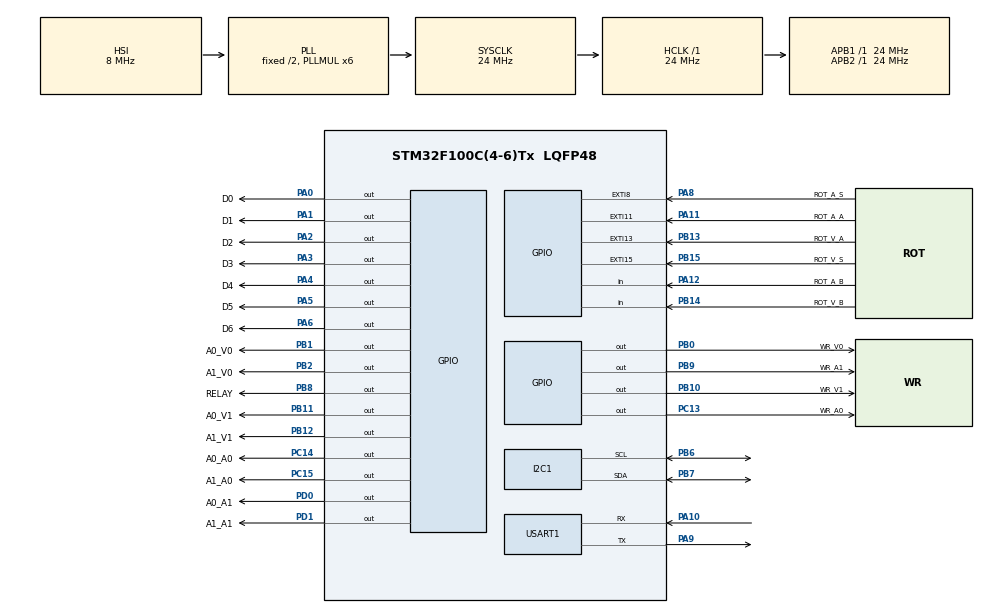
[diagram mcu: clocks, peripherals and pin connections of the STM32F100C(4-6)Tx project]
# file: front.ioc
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Mcu.Family=STM32F1
PB14.GPIO_Label=ROT_V_B
PA6.GPIO_Label=D6
PB0.GPIO_Label=WR_V0
PB13.GPIO_Label=ROT_V_A
PB11.Signal=GPIO_Output
PB13.Signal=GPXTI13
PB15.Signal=GPXTI15
PC15-OSC32_OUT.GPIO_Label=A1_A0
RCC.SYSCLKSource=RCC_SYSCLKSOURCE_PLLCLK
ProjectManager.StackSize=0x400
PD1-OSC_OUT.Signal=GPIO_Output
PD1-OSC_OUT.GPIO_Label=A1_A1
PA12.Signal=GPIO_Input
TIM15.Prescaler=24
RCC.HCLKFreq_Value=24000000
RCC.APB2TimFreq_Value=24000000
PB6.Signal=I2C1_SCL
PB6.Mode=I2C
RCC.AHBFreq_Value=24000000
NVIC.EXTI15_10_IRQn=true\:0\:0\:false\:false\:true\:true\:true
PB2.Signal=GPIO_Output
RCC.PLLMUL=RCC_PLL_MUL6
TIM15.Period=1000
PB12.GPIO_Label=A1_V1
PA14.Mode=Serial_Wire
PB1.GPIO_Label=A0_V0
PB7.Signal=I2C1_SDA
PA8.Signal=GPXTI8
Mcu.Package=LQFP48
PB9.Signal=GPIO_Output
PB1.Signal=GPIO_Output
PA6.Signal=GPIO_Output
PA2.GPIO_Label=D2
PA10.Signal=USART1_RX
RCC.APB1TimFreq_Value=24000000
PC14-OSC32_IN.GPIO_Label=A0_A0
NVIC.USART1_IRQn=true\:0\:0\:false\:false\:true\:true\:true
PA4.GPIO_Label=D4
PA3.Signal=GPIO_Output
PB9.GPIO_Label=WR_A1
PA10.Mode=Asynchronous
PB11.GPIO_Label=A0_V1
PC13-TAMPER-RTC.Signal=GPIO_Output
PA11.GPIO_Label=ROT_A_A
PD0-OSC_IN.Signal=GPIO_Output
PC14-OSC32_IN.Signal=GPIO_Output
PB13.GPIO_ModeDefaultEXTI=GPIO_MODE_IT_RISING_FALLING
PA12.GPIO_Label=ROT_A_B
PA0-WKUP.GPIO_Label=D0
PA0-WKUP.Signal=GPIO_Output
PA13.Signal=SYS_JTMS-SWDIO
PB8.GPIO_Label=RELAY
PA9.Mode=Asynchronous
PA8.GPIO_Label=ROT_A_S
ProjectManager.TargetToolchain=STM32CubeIDE
PB10.GPIO_Label=WR_V1
PA9.Signal=USART1_TX
PC15-OSC32_OUT.Signal=GPIO_Output
PA1.Signal=GPIO_Output
PB10.Signal=GPIO_Output
PB14.Signal=GPIO_Input
PA5.Signal=GPIO_Output
NVIC.TIM1_BRK_TIM15_IRQn=true\:0\:0\:false\:false\:true\:true\:true
board=custom
PD0-OSC_IN.GPIO_Label=A0_A1
PC13-TAMPER-RTC.GPIO_Label=WR_A0
RCC.APB2Freq_Value=24000000
PB15.GPIO_Label=ROT_V_S
PA1.GPIO_Label=D1
PA13.Mode=Serial_Wire
Mcu.Name=STM32F100C(4-6)Tx
PA2.Signal=GPIO_Output
PA4.Signal=GPIO_Output
RCC.SYSCLKFreq_VALUE=24000000
PA5.GPIO_Label=D5
USART1.VirtualMode=VM_ASYNC
PB7.Mode=I2C
PA11.Signal=GPXTI11
VP_TIM15_VS_ClockSourceINT.Mode=Internal
NVIC.EXTI9_5_IRQn=true\:0\:0\:false\:false\:true\:true\:true
PA14.Signal=SYS_JTCK-SWCLK
PB2.GPIO_Label=A1_V0
ProjectManager.HeapSize=0x200
NVIC.PriorityGroup=NVIC_PRIORITYGROUP_4
PB8.Signal=GPIO_Output
PA11.GPIO_ModeDefaultEXTI=GPIO_MODE_IT_RISING_FALLING
RCC.APB1Freq_Value=24000000
PB0.Signal=GPIO_Output
PB12.Signal=GPIO_Output
PA3.GPIO_Label=D3

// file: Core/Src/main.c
/* USER CODE BEGIN Header */
/**
  ******************************************************************************
  * @file           : main.c
  * @brief          : Main program body
  ******************************************************************************
  * @attention
  *
  * <h2><center>&copy; Copyright (c) 2021 STMicroelectronics.
  * All rights reserved.</center></h2>
  *
  * This software component is licensed by ST under BSD 3-Clause license,
  * the "License"; You may not use this file except in compliance with the
  * License. You may obtain a copy of the License at:
  *                        opensource.org/licenses/BSD-3-Clause
  *
  ******************************************************************************
  */
/* USER CODE END Header */
#include "main.h"
#include "i2c.h"
#include "tim.h"
#include "usart.h"
#include "gpio.h"

/* USER CODE BEGIN Includes */
#include "../../Application/Application/start.h"
/* USER CODE END Includes */

/* USER CODE BEGIN PV */
uint8_t globalUartReceiveBuffer[1];
/* USER CODE END PV */

void SystemClock_Config(void);

int main(void)
{

  /* MCU Configuration--------------------------------------------------------*/

  /* Reset of all peripherals, Initializes the Flash interface and the Systick. */
  HAL_Init();

  /* Configure the system clock */
  SystemClock_Config();

  /* Initialize all configured peripherals */
  MX_GPIO_Init();
  MX_TIM15_Init();
  MX_I2C1_Init();
  MX_USART1_UART_Init();
  /* USER CODE BEGIN 2 */
  HAL_UART_Receive_IT(&huart1, globalUartReceiveBuffer, 1);
  /* USER CODE END 2 */

  /* Infinite loop */
  while (1)
  {

    /* USER CODE BEGIN 3 */
	  start();
  }
  /* USER CODE END 3 */
}

void SystemClock_Config(void)
{
  RCC_OscInitTypeDef RCC_OscInitStruct = {0};
  RCC_ClkInitTypeDef RCC_ClkInitStruct = {0};

  /** Initializes the RCC Oscillators according to the specified parameters
  * in the RCC_OscInitTypeDef structure.
  */
  RCC_OscInitStruct.OscillatorType = RCC_OSCILLATORTYPE_HSI;
  RCC_OscInitStruct.HSIState = RCC_HSI_ON;
  RCC_OscInitStruct.HSICalibrationValue = RCC_HSICALIBRATION_DEFAULT;
  RCC_OscInitStruct.PLL.PLLState = RCC_PLL_ON;
  RCC_OscInitStruct.PLL.PLLSource = RCC_PLLSOURCE_HSI_DIV2;
  RCC_OscInitStruct.PLL.PLLMUL = RCC_PLL_MUL6;
  if (HAL_RCC_OscConfig(&RCC_OscInitStruct) != HAL_OK)
  {
    Error_Handler();
  }
  /** Initializes the CPU, AHB and APB buses clocks
  */
  RCC_ClkInitStruct.ClockType = RCC_CLOCKTYPE_HCLK|RCC_CLOCKTYPE_SYSCLK
                              |RCC_CLOCKTYPE_PCLK1|RCC_CLOCKTYPE_PCLK2;
  RCC_ClkInitStruct.SYSCLKSource = RCC_SYSCLKSOURCE_PLLCLK;
  RCC_ClkInitStruct.AHBCLKDivider = RCC_SYSCLK_DIV1;
  RCC_ClkInitStruct.APB1CLKDivider = RCC_HCLK_DIV1;
  RCC_ClkInitStruct.APB2CLKDivider = RCC_HCLK_DIV1;

  if (HAL_RCC_ClockConfig(&RCC_ClkInitStruct, FLASH_LATENCY_0) != HAL_OK)
  {
    Error_Handler();
  }
}

void Error_Handler(void)
{
  __disable_irq();
  while (1)
  {
  }
}

/************************ (C) COPYRIGHT STMicroelectronics *****END OF FILE****/
